# PIC32CX5112MTSH128S1 device description
Architecture: CORTEX-M4; Family: PIC32CXMT; Series: PIC32CXMTSH
Registers are 32-bit, read-write, no defined reset value unless marked. A register's access mark holds for its fields unless they carry their own. Offsets are from the block's base; [hi:lo] are bit positions; {n}, {i} and the like mark numbered series.

## GPBR — General Purpose Backup Registers
Instances: GPBR 0x40053060
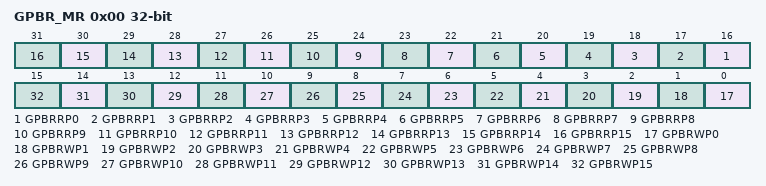
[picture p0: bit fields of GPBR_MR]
0x00 GPBR_MR — GPBR Mode Register
  [n+16] GPBRRP{n} (n=0..15) — GPBRx Read Protection
  [n] GPBRWP{n} (n=0..15) — GPBRx Write Protection
{0x8+4i} SYS_GPBR[{i}] (i=0..23) — General Purpose Backup Register
  [31:0] GPBR_VALUE — Value of SYS_GPBRx

## IPC — Inter-processor Communication
Instances: IPC0 0x4002C000, IPC1 0x48014000
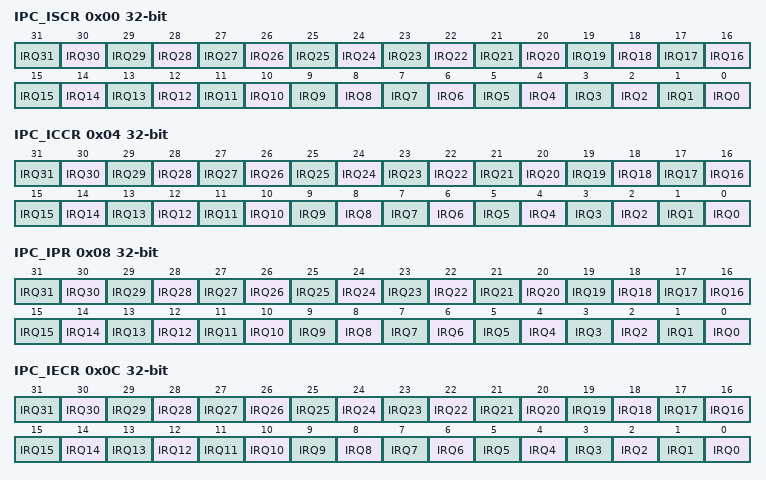
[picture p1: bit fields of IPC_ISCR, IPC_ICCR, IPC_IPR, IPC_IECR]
0x00 IPC_ISCR wo — Interrupt Set Command Register
  [n] IRQ{n} (n=0..31) — Interrupt Set
0x04 IPC_ICCR wo — Interrupt Clear Command Register
  [n] IRQ{n} (n=0..31) — Interrupt Clear
0x08 IPC_IPR ro — Interrupt Pending Register
  [n] IRQ{n} (n=0..31) — Interrupt Pending
0x0C IPC_IECR wo — Interrupt Enable Command Register
  [n] IRQ{n} (n=0..31) — Interrupt Enable
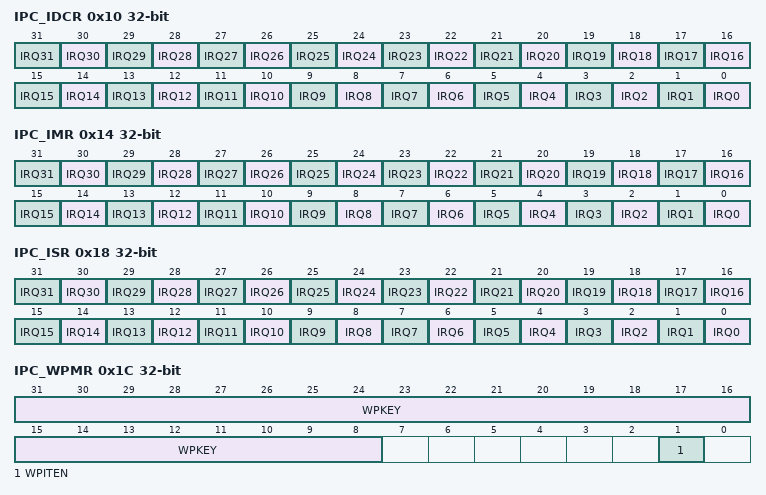
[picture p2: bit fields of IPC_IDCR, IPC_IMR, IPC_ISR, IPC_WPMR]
0x10 IPC_IDCR wo — Interrupt Disable Command Register
  [n] IRQ{n} (n=0..31) — Interrupt Disable
0x14 IPC_IMR ro — Interrupt Mask Register
  [n] IRQ{n} (n=0..31) — Interrupt Mask
0x18 IPC_ISR ro — Interrupt Status Register
  [n] IRQ{n} (n=0..31) — Current Interrupt Identifier
0x1C IPC_WPMR — Write Protection Mode Register
  [31:8] WPKEY — Write Protection Key
    0x495043=PASSWD (Writing any other value in this field aborts the write operation of the WPEN bit. Always reads as 0.)
  [1] WPITEN — Write Protection Interrupt Enable

## PDC — Peripheral DMA Controller
0x00 PERIPH_RPR — Receive Pointer Register
  [31:0] RXPTR
0x04 PERIPH_RCR — Receive Counter Register
  [15:0] RXCTR
0x08 PERIPH_TPR — Transmit Pointer Register
  [31:0] TXPTR — Transmit Counter Register
0x0C PERIPH_TCR — Transmit Counter Register
  [15:0] TXCTR
0x10 PERIPH_RNPR — Receive Next Pointer Register
  [31:0] RXNPTR — Receive Next Pointer
0x14 PERIPH_RNCR — Receive Next Counter Register
  [15:0] RXNCTR — Receive Next Counter
0x18 PERIPH_TNPR — Transmit Next Pointer Register
  [31:0] TXNPTR — Transmit Next Pointer
0x1C PERIPH_TNCR — Transmit Next Counter Register
  [15:0] TXNCTR — Transmit Counter Next
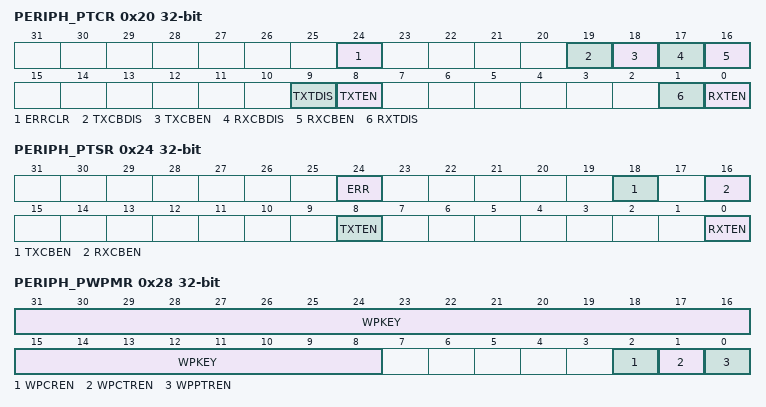
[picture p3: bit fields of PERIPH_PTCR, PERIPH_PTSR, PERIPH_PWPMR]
0x20 PERIPH_PTCR wo — Transfer Control Register
  [24] ERRCLR — Transfer Bus Error Clear
  [19] TXCBDIS — Transmitter Circular Buffer Disable
  [18] TXCBEN — Transmitter Circular Buffer Enable
  [17] RXCBDIS — Receiver Circular Buffer Disable
  [16] RXCBEN — Receiver Circular Buffer Enable
  [9] TXTDIS — Transmitter Transfer Disable
  [8] TXTEN — Transmitter Transfer Enable
  [1] RXTDIS — Receiver Transfer Disable
  [0] RXTEN — Receiver Transfer Enable
0x24 PERIPH_PTSR ro — Transfer Status Register
  [24] ERR — Transfer Bus Error
  [18] TXCBEN — Transmitter Circular Buffer Enable
  [16] RXCBEN — Receiver Circular Buffer Enable
  [8] TXTEN — Transmitter Transfer Enable
  [0] RXTEN — Receiver Transfer Enable
0x28 PERIPH_PWPMR — Write Protection Mode Register
  [31:8] WPKEY — Write Protection Key
    0x504443=PASSWD (Writing any other value in this field aborts the write operation. Always reads as 0.)
  [2] WPCREN — Write Protection Control Register Enable
  [1] WPCTREN — Write Protection Counter Registers Enable
  [0] WPPTREN — Write Protection Pointer Registers Enable

## RSTC — Reset Controller
Instances: RSTC 0x40053000
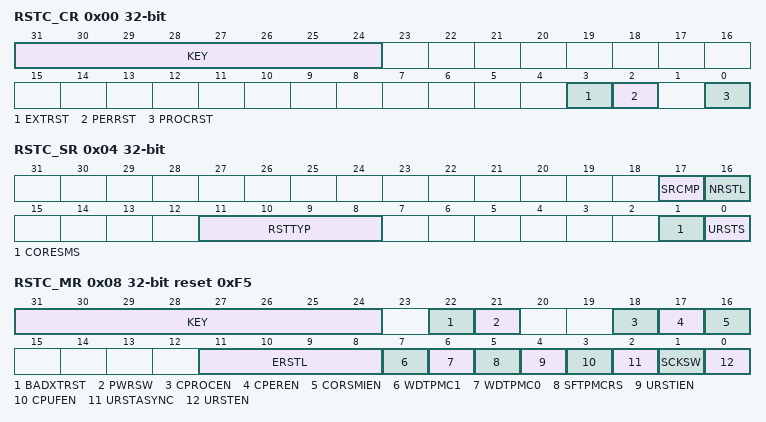
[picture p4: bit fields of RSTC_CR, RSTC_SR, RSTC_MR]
0x00 RSTC_CR wo — Control Register
  [31:24] KEY — System Reset Key
    165=PASSWD (Writing any other value in this field aborts the write operation.)
  [3] EXTRST — External Reset
  [2] PERRST — Peripheral Reset
  [0] PROCRST — Processor Reset
0x04 RSTC_SR ro — Status Register
  [17] SRCMP — Software Reset Command in Progress
  [16] NRSTL — NRST Pin Level
  [11:8] RSTTYP — Reset Type
    0=GENERAL_RST (First power-up reset, Core and VDD3V3 Supply Monitor if not a PORVDD3V3 reset); 1=BACKUP_RST (VDDCORE reset. Wake-up from Backup mode); 2=WDT0_RST (Watchdog 0 fault occurred); 3=SOFT_RST (Processor reset required by the software); 4=USER_RST (NRST pin detected low); 5=CORE_SM_RST (Core Supply Monitor reset); 6=CPU_FAIL_RST (CPU clock failure detection occurred); 7=SLCK_XTAL_RST (32.768 kHz crystal failure detection fault occurred); 9=WDT1_RST (Watchdog 1 fault occurred); 10=PORVDD3V3_RST (VDD3V3 PORVDD3V3 reset occurred)
  [1] CORESMS — VDDCORE Supply Monitor Reset Flag Status (cleared on read)
  [0] URSTS — User Reset Status (cleared on read)
0x08 RSTC_MR reset 0xF5 — Mode Register
  [31:24] KEY — Write Access Password
    165=PASSWD (Writing any other value in this field aborts the write operation. Always reads as 0.)
  [22] BADXTRST — Bad XTAL Fail Reset
  [21] PWRSW — Backup Area Power Switch Control
    0=VDD3V3 (VDDBU is supplied by VDD3V3); 1=VBAT (VDDBU is supplied by VBAT)
  [18] CPROCEN — Coprocessor (Second Processor) Enable
  [17] CPEREN — Coprocessor Peripheral Enable
  [16] CORSMIEN — VDDCORE Supply Monitor Interrupt Enable
  [11:8] ERSTL — External Reset Length
  [7] WDTPMC1 — WDT1 PMC Reset
  [6] WDTPMC0 — WDT0 PMC Reset
  [5] SFTPMCRS — Software PMC Reset
  [4] URSTIEN — User Reset Interrupt Enable
  [3] CPUFEN — CPU Fail Enable
  [2] URSTASYNC — User Reset Asynchronous Control
  [1] SCKSW — Slow Clock Switching
  [0] URSTEN — User Reset Enable
